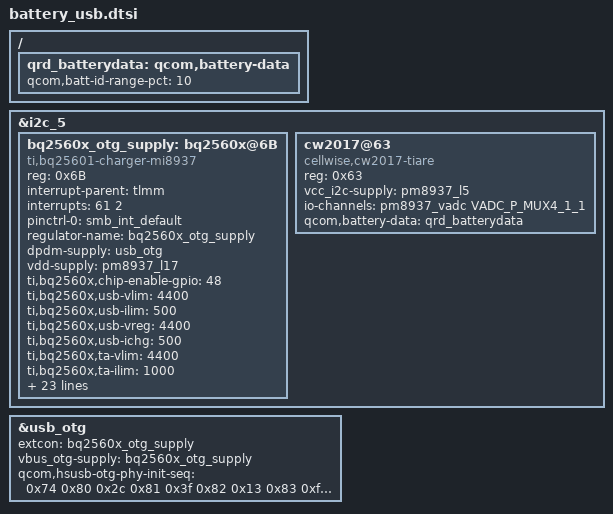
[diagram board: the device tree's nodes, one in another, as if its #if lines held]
/* From stock msm8917-pmi8937-qrd-sku5_S88508.dtsi */
&i2c_5 {
	bq2560x_otg_supply: bq2560x@6B {
#ifdef CONFIG_CHARGER_BQ2560X_MI8937
		compatible = "ti,bq25601-charger-mi8937";
#else
		compatible = "ti,bq25601-charger";
#endif
		reg = <0x6B>;
		interrupt-parent = <&tlmm>;
		interrupts = <61 2>;
		pinctrl-names = "default";
		pinctrl-0 = <&smb_int_default>;

		regulator-name = "bq2560x_otg_supply";
#ifndef CONFIG_MSM_USB_POWER_SUPPLY_MI8937
		dpdm-supply = <&usb_otg>;
#endif
		vdd-supply = <&pm8937_l17>;
		//qcom,bms-psy-name = "bms";

		ti,bq2560x,chip-enable-gpio = <48>;
		ti,bq2560x,usb-vlim = <4400>;
		ti,bq2560x,usb-ilim = <500>;
		ti,bq2560x,usb-vreg = <4400>;
		ti,bq2560x,usb-ichg = <500>;

		ti,bq2560x,ta-vlim = <4400>;
		ti,bq2560x,ta-ilim = <1000>;
		ti,bq2560x,ta-vreg = <4400>;
		ti,bq2560x,ta-ichg = <1000>;
		qcom,thermal-mitigation = <1000 800 700 0>;

		ti,bq2560x,precharge-current = <256>;
		ti,bq2560x,termination-current = <180>;
		ti,bq2560x,boost-voltage = <4998>;
		ti,bq2560x,boost-current = <500>;
		ti,bq2560x,enable_term;
		ti,bq2560x,stat-pin-ctrl = <0>;
		ti,bq2560x,vac-ovp-threshold = <6500>;

		ti,bq2560x,jeita-hot-degc = <550>;
		ti,bq2560x,jeita-warm-degc = <450>;
#ifdef CONFIG_CHARGER_BQ2560X_MI8937
		ti,bq2560x,jeita-cool-degc = <150>;
		ti,bq2560x,jeita-cool-xiaomi-degc = <50>;
#else
		ti,bq2560x,jeita-cool-normal-degc = <150>;
		ti,bq2560x,jeita-cold-cool-degc = <50>;
#endif
		ti,bq2560x,jeita-cold-degc = <0>;

		ti,bq2560x,jeita-hot-hysteresis = <20>;
		ti,bq2560x,jeita-cold-hysteresis = <10>;

#ifdef CONFIG_CHARGER_BQ2560X_MI8937
		ti,bq2560x,jeita-cool-xiaomi-ma = <300>;
		ti,bq2560x,jeita-cool-ma = <600>;
#else
		ti,bq2560x,jeita-cold-cool-ma = <300>;
		ti,bq2560x,jeita-cool-normal-ma = <600>;
#endif
		ti,bq2560x,jeita-cool-mv = <4400>;
		ti,bq2560x,jeita-warm-ma = <1000>;
		ti,bq2560x,jeita-warm-mv = <4100>;

		ti,bq2560x,software-jeita-supported;
	};

	cw2017@63 {
#ifdef CONFIG_GAUGE_CW2017_TIARE
		compatible = "cellwise,cw2017-tiare";
#else
		compatible = "cellwise,cw2017";
#endif
		reg = <0x63>;
		//vdd-supply = <&pm8937_l5>;
		vcc_i2c-supply = <&pm8937_l5>;
		//interrupt-parent = <&tlmm>;
		//interrupts = <46 2>;//cw2017 interrupt pin to gpio46, but not really use this interrupt
		//pinctrl-names = "default";
		//pinctrl-0 = <&cw_int_default>;
		io-channels = <&pm8937_vadc VADC_P_MUX4_1_1>;
		io-channel-names = "batt_id";
		qcom,battery-data = <&qrd_batterydata>;
	};
};
&usb_otg {
#ifndef CONFIG_MSM_USB_POWER_SUPPLY_MI8937
	extcon = <&bq2560x_otg_supply>;
#endif
	vbus_otg-supply = <&bq2560x_otg_supply>;
	qcom,hsusb-otg-phy-init-seq =
		<0x74 0x80 0x2c 0x81 0x3f 0x82 0x13 0x83 0xffffffff>;
};
/ {
	qrd_batterydata: qcom,battery-data {
		qcom,batt-id-range-pct = <10>;
		#include "batterydata/batterydata-xwd-4v4-3000mah.dtsi"
		#include "batterydata/batterydata-mingmei-4v4-3000mah.dtsi"
		#include "batterydata/batterydata-default-4v4-3000mah.dtsi"
	};
};
